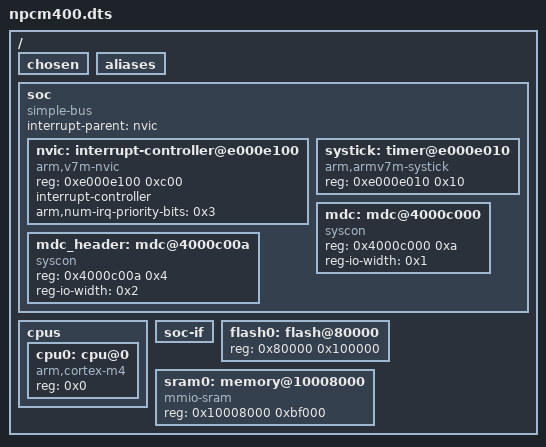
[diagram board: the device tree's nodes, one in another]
/dts-v1/;

/ {
	#address-cells = < 0x1 >;
	#size-cells = < 0x1 >;
	chosen {
	};
	aliases {
	};
	soc {
		#address-cells = < 0x1 >;
		#size-cells = < 0x1 >;
		compatible = "simple-bus";
		interrupt-parent = < &nvic >;
		ranges;
		nvic: interrupt-controller@e000e100 {
			#address-cells = < 0x1 >;
			compatible = "arm,v7m-nvic";
			reg = < 0xe000e100 0xc00 >;
			interrupt-controller;
			#interrupt-cells = < 0x2 >;
			arm,num-irq-priority-bits = < 0x3 >;
			phandle = < 0x1 >;
		};
		systick: timer@e000e010 {
			compatible = "arm,armv7m-systick";
			reg = < 0xe000e010 0x10 >;
		};
		mdc: mdc@4000c000 {
			compatible = "syscon";
			reg = < 0x4000c000 0xa >;
			reg-io-width = < 0x1 >;
		};
		mdc_header: mdc@4000c00a {
			compatible = "syscon";
			reg = < 0x4000c00a 0x4 >;
			reg-io-width = < 0x2 >;
		};
	};
	cpus {
		#address-cells = < 0x1 >;
		#size-cells = < 0x0 >;
		cpu0: cpu@0 {
			device_type = "cpu";
			compatible = "arm,cortex-m4";
			reg = < 0x0 >;
		};
	};
	soc-if {
	};
	flash0: flash@80000 {
		reg = < 0x80000 0x100000 >;
	};
	sram0: memory@10008000 {
		compatible = "mmio-sram";
		reg = < 0x10008000 0xbf000 >;
	};
};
